VERSION ""

NS_ :

BS_:

BU_:

BO_ 80 Science_Sensors: 20 science
 SG_ Sensors_Temperature : 0|32@1- (1,0) [-3.4E+38|3.4E+38] "celsius" jetson
 SG_ Sensors_Humidity : 32|32@1- [-3.4E+38|3.4E+38] "percent" jetson
 SG_ Sensors_UV : 64|32@1- [0|0] jetson
 SG_ Sensors_Oxygen : 96|32@1- jetson
 SG_ Sensors_CO2 : 128|32@1-

BO_ 81 Science_ISHOutbound: 12 science
 SG_ ISH_Heater1Temp : 0|32@1- (1,0) [0|0] "celsius" jetson
 SG_ ISH_Heater2Temp : 32|32@1- (1,0) [0|0] "celsius" jetson
 SG_ ISH_Heater1State : 64|1@1+ (1,0) [0|0] "" jetson
 SG_ ISH_Heater2State : 65|1@1+ (1,0) [0|0] "" jetson
 SG_ ISH_WLED1State : 66|1@1+ (1,0) [0|0] "" jetson
 SG_ ISH_WLED2State : 67|1@1+ (1,0) [0|0] "" jetson

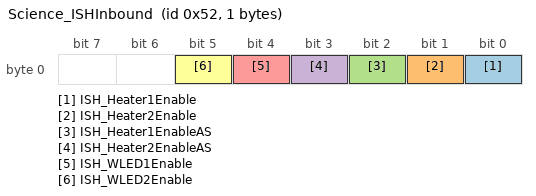
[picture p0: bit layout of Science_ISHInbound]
BO_ 82 Science_ISHInbound: 1 jetson
 SG_ ISH_Heater1Enable : 0|1@1+ (1,0) [0|0] "" science
 SG_ ISH_Heater2Enable : 1|1@1+ (1,0) [0|0] "" science
 SG_ ISH_Heater1EnableAS : 2|1@1+ (1,0) [0|0] "" science
 SG_ ISH_Heater2EnableAS : 3|1@1+ (1,0) [0|0] "" science
 SG_ ISH_WLED1Enable : 4|1@1+ (1,0) [0|0] "" science
 SG_ ISH_WLED2Enable : 5|1@1+ (1,0) [0|0] "" science

CM_ BO_ 80 "sensor information from the
science

board
"

CM_ SG_ 80 Sensors_Humidity "percent relative humidity";

BA_DEF_ BO_  "CANFD_BRS" ENUM  "0","1";
BA_DEF_  "BusType" STRING ;
BA_DEF_ BO_  "VFrameFormat" ENUM  "StandardCAN","ExtendedCAN","reserved","reserved","reserved","reserved","reserved","reserved","reserved","reserved","reserved","reserved","reserved","reserved","StandardCAN_FD","ExtendedCAN_FD";
BA_DEF_DEF_  "CANFD_BRS" "1";
BA_DEF_DEF_  "BusType" "";
BA_DEF_DEF_  "VFrameFormat" "StandardCAN";
BA_ "BusType" "CAN FD";
BA_ "VFrameFormat" BO_ 80 14;
BA_ "VFrameFormat" BO_ 81 14;
BA_ "VFrameFormat" BO_ 82 14;
SIG_VALTYPE_ 80 Sensors_Temperature : 1;
SIG_VALTYPE_ 80 Sensors_Humidity : 1;
SIG_VALTYPE_ 80 Sensors_UV : 1;
SIG_VALTYPE_ 80 Sensors_Oxygen : 1;
SIG_VALTYPE_ 80 Sensors_CO2 : 1;
SIG_VALTYPE_ 81 ISH_Heater1Temp : 1;
SIG_VALTYPE_ 81 ISH_Heater2Temp : 1;
